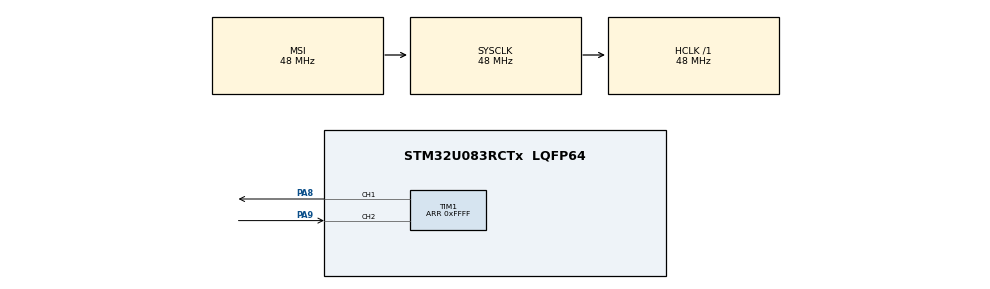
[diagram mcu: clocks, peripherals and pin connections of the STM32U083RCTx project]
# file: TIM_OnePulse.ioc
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Mcu.Family=STM32U0
Mcu.Name=STM32U083RCTx
Mcu.Package=LQFP64
PA8.GPIO_PuPd=GPIO_PULLDOWN
PA8.GPIO_Speed=GPIO_SPEED_FREQ_VERY_HIGH
PA8.Signal=S_TIM1_CH1
PA9.GPIO_PuPd=GPIO_PULLDOWN
PA9.GPIO_Speed=GPIO_SPEED_FREQ_VERY_HIGH
PA9.Signal=S_TIM1_CH2
ProjectManager.HeapSize=0x200
ProjectManager.StackSize=0x400
ProjectManager.TargetToolchain=EWARM V9.20
RCC.ADCFreq_Value=48000000
RCC.AHBFreq_Value=48000000
RCC.CortexFreq_Value=48000000
RCC.HCLKFreq_Value=48000000
RCC.HSE_VALUE=4000000
RCC.HSI48_VALUE=48000000
RCC.HSI_VALUE=16000000
RCC.LSE_VALUE=32768
RCC.MSIClockRangeVal=RCC_MSIRANGE_11
RCC.MSI_VALUE=48000000
RCC.PLLM=RCC_PLLM_DIV8
RCC.PLLN=8
RCC.PLLSourceVirtual=RCC_PLLSOURCE_MSI
RCC.SYSCLKFreq_VALUE=48000000
RCC.SYSCLKSource=RCC_SYSCLKSOURCE_MSI
RCC.USBFreq_Value=48000000
RCC.VCOOutputFreq_Value=48000000
SH.S_TIM1_CH1.0=TIM1_CH1,PWM Generation1 CH1
SH.S_TIM1_CH2.0=TIM1_CH2,TriggerSource_TI2FP2
TIM1.AutoReloadPreload=TIM_AUTORELOAD_PRELOAD_DISABLE
TIM1.AutomaticOutput=TIM_AUTOMATICOUTPUT_DISABLE
TIM1.Break2Filter=0
TIM1.Break2Polarity=TIM_BREAK2POLARITY_HIGH
TIM1.Break2State=TIM_BREAK2_DISABLE
TIM1.BreakFilter=0
TIM1.BreakPolarity=TIM_BREAKPOLARITY_HIGH
TIM1.BreakState=TIM_BREAK_DISABLE
TIM1.Channel-PWM\ Generation1\ CH1=TIM_CHANNEL_1
TIM1.ClearInputSource=TIM_CLEARINPUTSOURCE_NONE
TIM1.ClockDivision=TIM_CLOCKDIVISION_DIV1
TIM1.CounterMode=TIM_COUNTERMODE_UP
TIM1.LockLevel=TIM_LOCKLEVEL_OFF
TIM1.OC1Preload_PWM=ENABLE
TIM1.OCFastMode_PWM-PWM\ Generation1\ CH1=TIM_OCFAST_DISABLE
TIM1.OCIdleState_1=TIM_OCIDLESTATE_RESET
TIM1.OCMode_PWM-PWM\ Generation1\ CH1=TIM_OCMODE_PWM2
TIM1.OCPolarity_1=TIM_OCPOLARITY_HIGH
TIM1.OffStateIDLEMode=TIM_OSSI_DISABLE
TIM1.OffStateRunMode=TIM_OSSR_DISABLE
TIM1.Period=0xFFFF
TIM1.Prescaler=PRESCALER_VALUE
TIM1.Pulse-PWM\ Generation1\ CH1=16383
TIM1.RepetitionCounter=0
TIM1.Slave_TriggerFilter=0
TIM1.SourceBRK2COMP1=TIM_BREAKINPUTSOURCE_DISABLE
TIM1.SourceBRK2COMP2=TIM_BREAKINPUTSOURCE_DISABLE
TIM1.SourceBRK2DigInput=TIM_BREAKINPUTSOURCE_DISABLE
TIM1.SourceBRKCOMP1=TIM_BREAKINPUTSOURCE_DISABLE
TIM1.SourceBRKCOMP2=TIM_BREAKINPUTSOURCE_DISABLE
TIM1.SourceBRKDigInput=TIM_BREAKINPUTSOURCE_DISABLE
TIM1.TIM_MasterOutputTrigger=TIM_TRGO_RESET
TIM1.TIM_MasterOutputTrigger2=TIM_TRGO2_RESET
TIM1.TIM_MasterSlaveMode=TIM_MASTERSLAVEMODE_DISABLE
TIM1.TIM_SlaveMode=TIM_SLAVEMODE_TRIGGER
VP_PWR_VS_SECSignals.Mode=Security/Privilege
VP_TIM1_VS_ControllerModeTrigger.Mode=Trigger Mode
VP_TIM1_VS_OPM.Mode=OPM_bit
board=custom

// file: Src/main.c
/* USER CODE BEGIN Header */
/**
  ******************************************************************************
  * @file    TIM/TIM_OnePulse/Src/main.c
  * @author  MCD Application Team
  * @brief   This sample code shows how to use TIM HAL API to generate
  *          a one pulse signal
  ******************************************************************************
  * @attention
  *
  * Copyright (c) 2023 STMicroelectronics.
  * All rights reserved.
  *
  * This software is licensed under terms that can be found in the LICENSE file
  * in the root directory of this software component.
  * If no LICENSE file comes with this software, it is provided AS-IS.
  *
  ******************************************************************************
  */
/* USER CODE END Header */
#include "main.h"

TIM_HandleTypeDef htim1;

void SystemClock_Config(void);
static void MX_GPIO_Init(void);
static void MX_TIM1_Init(void);

int main(void)
{
  /* USER CODE BEGIN 1 */

  /* STM32U0xx HAL library initialization:
       - Configure the Flash prefetch
       - Systick timer is configured by default as source of time base, but user
         can eventually implement his proper time base source (a general purpose
         timer for example or other time source), keeping in mind that Time base
         duration should be kept 1ms since PPP_TIMEOUT_VALUEs are defined and
         handled in milliseconds basis.
       - Low Level Initialization
     */
  /* USER CODE END 1 */

  /* MCU Configuration--------------------------------------------------------*/

  /* Reset of all peripherals, Initializes the Flash interface and the Systick. */
  HAL_Init();

  /* Configure the system clock */
  SystemClock_Config();

  /* USER CODE BEGIN SysInit */

  /* Configure LED4 */
  BSP_LED_Init(LED4);

  /* USER CODE END SysInit */

  /* Initialize all configured peripherals */
  MX_GPIO_Init();
  MX_TIM1_Init();
  /* USER CODE BEGIN 2 */

  /*## Start the One Pulse mode #######################################
   *
   * * The one pulse waveform can be displayed using an oscilloscope and it looks
   * like this.
   *                              ____
   *                              |   |
   * CH2 _________________________|   |_________________________________________
   *
   *                                            ___________________________
   *                                           |                           |
   * CH1 ______________________________________|                           |____
   *                             <---Delay-----><------Pulse--------------->
   */

  if (HAL_TIM_PWM_Start(&htim1, TIM_CHANNEL_1) != HAL_OK)
  {
    /* Starting Error */
    Error_Handler();
  }

  /* USER CODE END 2 */

  /* Infinite loop */
  while (1)
  {

  }
}

void SystemClock_Config(void)
{
  RCC_OscInitTypeDef RCC_OscInitStruct = {0};
  RCC_ClkInitTypeDef RCC_ClkInitStruct = {0};

  /** Configure the main internal regulator output voltage
  */
  HAL_PWREx_ControlVoltageScaling(PWR_REGULATOR_VOLTAGE_SCALE1);

  /** Initializes the RCC Oscillators according to the specified parameters
  * in the RCC_OscInitTypeDef structure.
  */
  RCC_OscInitStruct.OscillatorType = RCC_OSCILLATORTYPE_MSI;
  RCC_OscInitStruct.MSIState = RCC_MSI_ON;
  RCC_OscInitStruct.MSICalibrationValue = RCC_MSICALIBRATION_DEFAULT;
  RCC_OscInitStruct.MSIClockRange = RCC_MSIRANGE_11;
  RCC_OscInitStruct.PLL.PLLState = RCC_PLL_NONE;
  if (HAL_RCC_OscConfig(&RCC_OscInitStruct) != HAL_OK)
  {
    Error_Handler();
  }

  /** Initializes the CPU, AHB and APB buses clocks
  */
  RCC_ClkInitStruct.ClockType = RCC_CLOCKTYPE_HCLK|RCC_CLOCKTYPE_SYSCLK
                              |RCC_CLOCKTYPE_PCLK1;
  RCC_ClkInitStruct.SYSCLKSource = RCC_SYSCLKSOURCE_MSI;
  RCC_ClkInitStruct.AHBCLKDivider = RCC_SYSCLK_DIV1;
  RCC_ClkInitStruct.APB1CLKDivider = RCC_HCLK_DIV1;

  if (HAL_RCC_ClockConfig(&RCC_ClkInitStruct, FLASH_LATENCY_1) != HAL_OK)
  {
    Error_Handler();
  }
}

static void MX_TIM1_Init(void)
{

  TIM_SlaveConfigTypeDef sSlaveConfig = {0};
  TIM_MasterConfigTypeDef sMasterConfig = {0};
  TIM_OC_InitTypeDef sConfigOC = {0};
  TIM_BreakDeadTimeConfigTypeDef sBreakDeadTimeConfig = {0};

  htim1.Instance = TIM1;
  htim1.Init.Prescaler = PRESCALER_VALUE;
  htim1.Init.CounterMode = TIM_COUNTERMODE_UP;
  htim1.Init.Period = 0xFFFF;
  htim1.Init.ClockDivision = TIM_CLOCKDIVISION_DIV1;
  htim1.Init.RepetitionCounter = 0;
  htim1.Init.AutoReloadPreload = TIM_AUTORELOAD_PRELOAD_DISABLE;
  if (HAL_TIM_Base_Init(&htim1) != HAL_OK)
  {
    Error_Handler();
  }
  if (HAL_TIM_PWM_Init(&htim1) != HAL_OK)
  {
    Error_Handler();
  }
  if (HAL_TIM_OnePulse_Init(&htim1, TIM_OPMODE_SINGLE) != HAL_OK)
  {
    Error_Handler();
  }
  sSlaveConfig.SlaveMode = TIM_SLAVEMODE_TRIGGER;
  sSlaveConfig.InputTrigger = TIM_TS_TI2FP2;
  sSlaveConfig.TriggerPolarity = TIM_TRIGGERPOLARITY_RISING;
  sSlaveConfig.TriggerFilter = 0;
  if (HAL_TIM_SlaveConfigSynchro(&htim1, &sSlaveConfig) != HAL_OK)
  {
    Error_Handler();
  }
  sMasterConfig.MasterOutputTrigger = TIM_TRGO_RESET;
  sMasterConfig.MasterOutputTrigger2 = TIM_TRGO2_RESET;
  sMasterConfig.MasterSlaveMode = TIM_MASTERSLAVEMODE_DISABLE;
  if (HAL_TIMEx_MasterConfigSynchronization(&htim1, &sMasterConfig) != HAL_OK)
  {
    Error_Handler();
  }
  sConfigOC.OCMode = TIM_OCMODE_PWM2;
  sConfigOC.Pulse = 16383;
  sConfigOC.OCPolarity = TIM_OCPOLARITY_HIGH;
  sConfigOC.OCNPolarity = TIM_OCNPOLARITY_HIGH;
  sConfigOC.OCFastMode = TIM_OCFAST_DISABLE;
  sConfigOC.OCIdleState = TIM_OCIDLESTATE_RESET;
  sConfigOC.OCNIdleState = TIM_OCNIDLESTATE_RESET;
  if (HAL_TIM_PWM_ConfigChannel(&htim1, &sConfigOC, TIM_CHANNEL_1) != HAL_OK)
  {
    Error_Handler();
  }
  sBreakDeadTimeConfig.OffStateRunMode = TIM_OSSR_DISABLE;
  sBreakDeadTimeConfig.OffStateIDLEMode = TIM_OSSI_DISABLE;
  sBreakDeadTimeConfig.LockLevel = TIM_LOCKLEVEL_OFF;
  sBreakDeadTimeConfig.DeadTime = 0;
  sBreakDeadTimeConfig.BreakState = TIM_BREAK_DISABLE;
  sBreakDeadTimeConfig.BreakPolarity = TIM_BREAKPOLARITY_HIGH;
  sBreakDeadTimeConfig.BreakFilter = 0;
  sBreakDeadTimeConfig.BreakAFMode = TIM_BREAK_AFMODE_INPUT;
  sBreakDeadTimeConfig.Break2State = TIM_BREAK2_DISABLE;
  sBreakDeadTimeConfig.Break2Polarity = TIM_BREAK2POLARITY_HIGH;
  sBreakDeadTimeConfig.Break2Filter = 0;
  sBreakDeadTimeConfig.Break2AFMode = TIM_BREAK_AFMODE_INPUT;
  sBreakDeadTimeConfig.AutomaticOutput = TIM_AUTOMATICOUTPUT_DISABLE;
  if (HAL_TIMEx_ConfigBreakDeadTime(&htim1, &sBreakDeadTimeConfig) != HAL_OK)
  {
    Error_Handler();
  }
  HAL_TIM_MspPostInit(&htim1);

}

static void MX_GPIO_Init(void)
{

  /* GPIO Ports Clock Enable */
  __HAL_RCC_GPIOA_CLK_ENABLE();

}

void Error_Handler(void)
{
  /* USER CODE BEGIN Error_Handler_Debug */
  /* Turn LED4 on */
  BSP_LED_On(LED4);
  while(1)
  {
  }
  /* USER CODE END Error_Handler_Debug */
}
